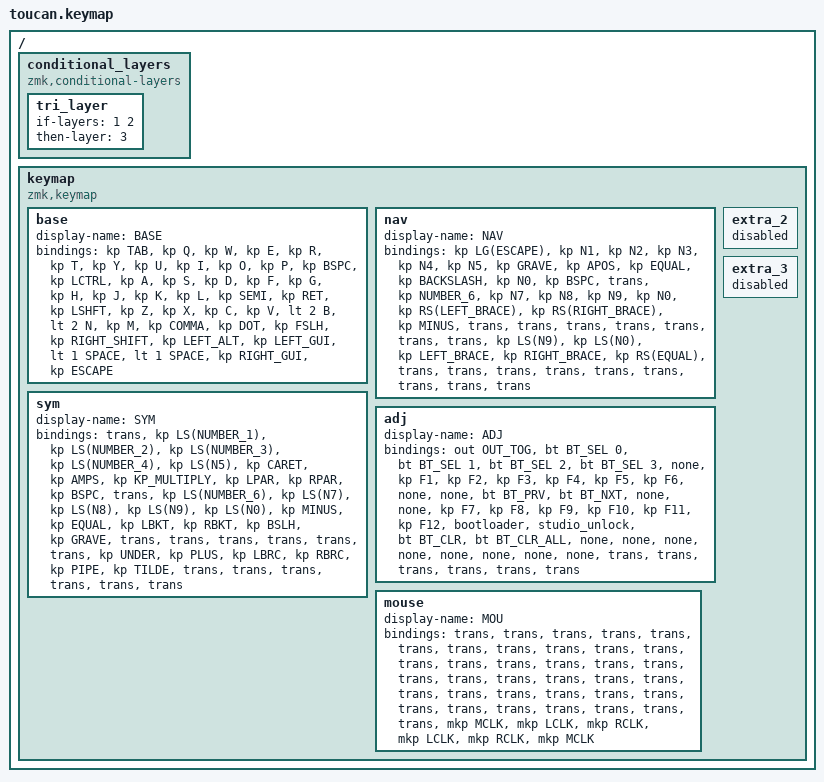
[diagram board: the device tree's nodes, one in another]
#include <behaviors.dtsi>
#include <dt-bindings/zmk/bt.h>
#include <dt-bindings/zmk/keys.h>
#include <dt-bindings/zmk/outputs.h>
#include <dt-bindings/zmk/pointing.h>

#define BASE 0
#define NAV  1
#define SYM  2
#define ADJ  3

/ {
    conditional_layers {
        compatible = "zmk,conditional-layers";

        tri_layer {
            if-layers = <1 2>;
            then-layer = <3>;
        };
    };

    keymap {
        compatible = "zmk,keymap";

        base {
            display-name = "BASE";
            bindings = <
&kp TAB  &kp Q  &kp W  &kp E  &kp R  &kp T  &kp Y  &kp U  &kp I  &kp O  &kp P  &kp BSPC  &kp LCTRL  &kp A  &kp S  &kp D  &kp F  &kp G  &kp H  &kp J  &kp K  &kp L  &kp SEMI  &kp RET  &kp LSHFT  &kp Z  &kp X  &kp C  &kp V  &lt 2 B  &lt 2 N  &kp M  &kp COMMA  &kp DOT  &kp FSLH  &kp RIGHT_SHIFT  &kp LEFT_ALT  &kp LEFT_GUI  &lt 1 SPACE  &lt 1 SPACE  &kp RIGHT_GUI  &kp ESCAPE
            >;
        };

        nav {
            display-name = "NAV";
            bindings = <
&kp LG(ESCAPE)  &kp N1  &kp N2  &kp N3  &kp N4  &kp N5  &kp GRAVE  &kp APOS  &kp EQUAL  &kp BACKSLASH  &kp N0  &kp BSPC  &trans  &kp NUMBER_6  &kp N7  &kp N8  &kp N9  &kp N0  &kp RS(LEFT_BRACE)  &kp RS(RIGHT_BRACE)  &kp MINUS  &trans  &trans  &trans  &trans  &trans  &trans  &trans  &kp LS(N9)  &kp LS(N0)  &kp LEFT_BRACE  &kp RIGHT_BRACE  &kp RS(EQUAL)  &trans  &trans  &trans  &trans  &trans  &trans  &trans  &trans  &trans
            >;
        };

        sym {
            display-name = "SYM";
            bindings = <
&trans  &kp LS(NUMBER_1)  &kp LS(NUMBER_2)  &kp LS(NUMBER_3)  &kp LS(NUMBER_4)  &kp LS(N5)  &kp CARET  &kp AMPS  &kp KP_MULTIPLY  &kp LPAR  &kp RPAR  &kp BSPC  &trans  &kp LS(NUMBER_6)  &kp LS(N7)  &kp LS(N8)  &kp LS(N9)  &kp LS(N0)  &kp MINUS  &kp EQUAL  &kp LBKT  &kp RBKT  &kp BSLH  &kp GRAVE  &trans  &trans  &trans  &trans  &trans  &trans  &kp UNDER  &kp PLUS  &kp LBRC  &kp RBRC  &kp PIPE  &kp TILDE  &trans  &trans  &trans  &trans  &trans  &trans
            >;
        };

        adj {
            display-name = "ADJ";
            bindings = <
&out OUT_TOG  &bt BT_SEL 0  &bt BT_SEL 1  &bt BT_SEL 2  &bt BT_SEL 3  &none  &kp F1  &kp F2  &kp F3  &kp F4  &kp F5  &kp F6  &none  &none  &bt BT_PRV  &bt BT_NXT  &none  &none  &kp F7  &kp F8  &kp F9  &kp F10  &kp F11  &kp F12  &bootloader  &studio_unlock  &bt BT_CLR  &bt BT_CLR_ALL  &none  &none  &none  &none  &none  &none  &none  &none  &trans  &trans  &trans  &trans  &trans  &trans
            >;
        };

        mouse {
            display-name = "MOU";
            bindings = <
&trans  &trans  &trans  &trans  &trans  &trans  &trans  &trans  &trans  &trans  &trans  &trans  &trans  &trans  &trans  &trans  &trans  &trans  &trans  &trans  &trans  &trans  &trans  &trans  &trans  &trans  &trans  &trans  &trans  &trans  &trans  &trans  &trans  &trans  &trans  &trans  &mkp MCLK  &mkp LCLK  &mkp RCLK  &mkp LCLK  &mkp RCLK  &mkp MCLK
            >;
        };

        extra_2 { status = "reserved"; };

        extra_3 { status = "reserved"; };
    };
};
